# STM32U5Gx register map
File version: 1.0
CPU: CM33 r0p1, little endian, MPU, FPU, 4 interrupt priority bits
Registers are 32-bit, read-write, reset 0x0 unless marked. A register's access mark holds for its fields unless they carry their own. Offsets are from the block's base; [hi:lo] are bit positions; {n}, {i} and the like mark numbered series; 'fields as' and 'values as' point back to an identical list.

## GPDMA1 (part 1 of 2)
Base 0x40020000
Same registers: SEC_GPDMA1 0x50020000
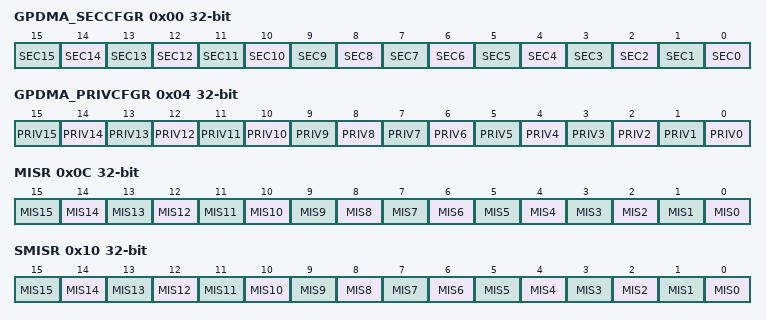
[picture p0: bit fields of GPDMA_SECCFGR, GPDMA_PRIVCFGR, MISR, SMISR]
0x00 GPDMA_SECCFGR — GPDMA secure configuration register
  [n] SEC{n} (n=0..15)
0x04 GPDMA_PRIVCFGR — GPDMA privileged configuration register
  [n] PRIV{n} (n=0..15)
0x0C MISR ro — non-secure masked interrupt status register
  [n] MIS{n} (n=0..15)
0x10 SMISR ro — secure masked interrupt status register
  [n] MIS{n} (n=0..15)
{0x50+0x80*i} GPDMA_C{i}LBAR (i=0..15) — channel x linked-list base address register
  [31:16] LBA — linked-list base address of DMA channel x
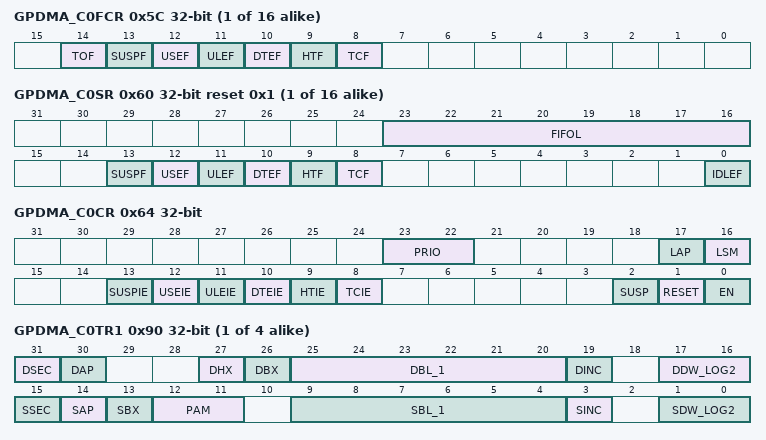
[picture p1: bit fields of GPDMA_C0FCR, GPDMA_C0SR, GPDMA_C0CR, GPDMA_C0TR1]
{0x5C+0x80*i} GPDMA_C{i}FCR wo (i=0..15) — GPDMA channel x flag clear register
  [14] TOF — trigger overrun flag clear
  [13] SUSPF — completed suspension flag clear - 0: no effect - 1: clears the corresponding SUSPF flag
  [12] USEF — user setting error flag clear - 0: no effect - 1: clears the corresponding USEF flag
  [11] ULEF — update link transfer error flag clear - 0: no effect - 1: clears the corresponding ULEF flag
  [10] DTEF — data transfer error flag clear - 0: no effect - 1: clears the corresponding DTEF flag
  [9] HTF — half transfer flag clear - 0: no effect - 1: clears the corresponding HTF flag
  [8] TCF — transfer complete flag clear - 0: no effect - 1: clears the corresponding TCF flag
{0x60+0x80*i} GPDMA_C{i}SR ro reset 0x1 (i=0..15) — channel x status register
  [23:16] FIFOL — monitored FIFO level Number of available write beats in the FIFO, in units of the programmed destination data width (c.f. GPDMA_CxTR1.DDW_LOG2[1:0], i.e. in units of bytes, half-words, or words). Note: After having suspended an active transfer, the user may need to read FIFOL[7:0], additionally to GPDMA_CxBR1.BDNT[15:0] and GPDMA_CxBR1.BRC[10:0] in order to know exactly how many data have been transferred to the destination. Before reading, the user may wait for the transfer to be indeed suspended i.e. GPDMA_CxSR.SUSPF=1.
  [13] SUSPF — completed suspension flag - 0: no completed suspension event - 1: a completed suspension event occurred
  [12] USEF — user setting error flag - 0: no user setting error event - 1: a user setting error event occurred
  [11] ULEF — update link transfer error flag - 0: no update link transfer error event - 1: a master bus error event occurred while updating a linked-list register from memory
  [10] DTEF — data transfer error flag - 0: no data transfer error event - 1: a master bus error event occurred on a data transfer
  [9] HTF — half transfer flag - 0: no half transfer event - 1: an half transfer event occurred An half transfer event is either an half block transfer or an half 2D/repeated block transfer, depending on the transfer complete event mode i.e. GPDMA_CxTR2.TCEM[1:0]. An half block transfer occurs when half of the bytes of the source block size (i.e. rounded up integer of GPDMA_CxBR1.BNDT[15:0]/2) has been transferred to the destination. Half 2D/repeated block transfer occurs when half of the repeated blocks (i.e. rounded up integer of (GPDMA_CxBR1.BRC[10:0]+1)/2) have been transferred to the destination.
  [8] TCF — transfer complete flag - 0: no transfer complete event - 1: a transfer complete event occurred A transfer complete event is either a block transfer complete or a 2D/repeated block transfer complete, or a LLI transfer complete including the upload of the next LLI if any, or the full linked-list completion, depending on the transfer complete event mode i.e. GPDMA_CxTR2.TCEM[1:0].
  [0] IDLEF — idle flag - 0: the channel is not in idle state - 1: the channel is in idle state This idle flag is de-asserted by hardware when the channel is enabled (i.e. is written 1 into GPDMA_CxCR.EN) with a valid channel configuration (i.e. no USEF to be immediately reported). This idle flag is asserted after hard reset or by hardware when the channel is back in idle state (i.e. in suspended or disabled state).
0x64 GPDMA_C0CR — channel x control register
  [23:22] PRIO — priority level of the DMA transfer of the channel x vs others- 00: low priority, low weight- 01: low priority, mid weight- 10: low priority, high weight- 11: high priorityNote: This bit must be written when EN=0. This bit is read-only when EN=1.
  [17] LAP — linked-list allocated portAllocate the master port for the update of the DMA linked-list registers from the memory.- 0: port 0 (AHB) is allocated for the update of the DMA linked-list channel x registers- 1: port 1 (AHB) is allocated for the update of the DMA linked-list channel x registersNote: This bit must be written when EN=0. This bit is read-only when EN=1.
  [16] LSM — Link Step mode:- 0: channel is executed for the full linked-list, and completed at the end (if any) of the last LLI i.e. when GPDMA_CxLLR=0: the 16 low significant bits of the link address are null (LA[15:0]=0) and all the update bits are null i.e. UT1=UB1=UT2=USA=UDA=UB2 =UT3=ULL=0. Then GPDMA_CxBR1.BRC[10:0]=0 and GPDMA_CxBR1.BNDT[15:0]=0.- 1: channel is executed once for the current LLI:* First the (possibly 2D/repeated) block transfer is executed as defined by the current internal register file until that (GPDMA_CxBR1.BRC[10:0]=0 and GPDMA_CxBR1.BNDT[15:0]=0).* Secondly the next linked-list data structure is conditionally uploaded from memory as defined by GPDMA_CxLLR register. Then channel execution is completed.Note: This bit must be written when EN=0. This bit is read-only when EN=1.
  [13] SUSPIE — completed suspension interrupt enable - 0: interrupt disabled - 1: interrupt enabled
  [12] USEIE — user setting error interrupt enable - 0: interrupt disabled - 1: interrupt enabled
  [11] ULEIE — update link transfer error interrupt enable - 0: interrupt disabled - 1: interrupt enabled
  [10] DTEIE — data transfer error interrupt enable - 0: interrupt disabled - 1: interrupt enabled
  [9] HTIE — half transfer complete interrupt enable - 0: interrupt disabled - 1: interrupt enabled
  [8] TCIE — transfer complete interrupt enable - 0: interrupt disabled - 1: interrupt enabled
  [2] SUSP — suspend - 0: write: resume channel, read: channel not suspended - 1: write: suspend channel, read: channel suspended Writing 1 into the field RESET (bit 1) causes the hardware to de-assert this bit, whatever is written into this bit 2. Else: Software must write 1 in order to suspend an active channel i.e. a channel with an on-going DMA transfer over its master ports. Software must write 0 in order to resume a suspended channel, following the programming sequence in Figure 3: DMA channel suspend and resume sequence.
  [1] RESET — reset - 0: no channel reset - 1: channel reset This bit is write only. Writing 0 has no impact. Writing 1 implies/will imply the reset of the FIFO, the reset of the channel internal state, and the reset of the SUSP and EN bits, whatever is written in respectively bit 2 and bit 0.
  [0] EN — enable - 0: write: ignored, read: channel disabled - 1: write: enable channel, read: channel enabled Writing 1 into the field RESET (bit 1) causes the hardware to de-assert this bit, whatever is written into this bit 0. Else: * this bit is de-asserted by hardware when there is a transfer error (master bus error or user setting error) or when there is a channel transfer complete (channel ready to be configured, e.g. if LSM=1 at the end of a single execution of the LLI). * Else, this bit can be asserted by software. Writing 0 into this EN bit is ignored.
{0x90+0x80*i} GPDMA_C{i}TR1 (i=0..3) — GPDMA channel x transfer register 1
  [31] DSEC — security attribute of the DMA transfer to the destinationThis is a secure register bit.This bit can only be read by a secure software. This bit must be written by a secure software when GPDMA_SECCFGR.SECx=1. A secure write is ignored when GPDMA_SECCFGR.SECx=0.When is de-asserted GPDMA_SECCFGR.SECx, this bit is also de-asserted by hardware (on a secure reconfiguration of the channel as non-secure), and the DMA transfer to the destination is non-secure.If GPDMA_SECCFGR.SECx=1 (and a secure access):- 0: non-secure- 1: secure
  [30] DAP — destination allocated portAllocate the master port to the destination transfer.- 0: port 0 (AHB) is allocated to the destination transfer- 1: port 1 (AHB) is allocated to the destination transferNote: This bit must be written when EN=0. This bit is read-only when EN=1.
  [27] DHX — destination half-word exchangeIf destination data size is shorter than a word, this bit is ignored.If destination data size is a word:- 0: no halfword-based exchange within word- 1: the two consecutive (post PAM) half-words are exchanged in each destination word
  [26] DBX — destination byte exchangeIf destination data size is a byte, this bit is ignored.If destination data size is not a byte:- 0: no byte-based exchange within half-word- 1: the two consecutive (post PAM) bytes are exchanged in each destination half-word
  [25:20] DBL_1 — destination burst length minus 1 , between 0 and 63.Burst length unit is one data a.k.a. beat within a burst.If DBL_1[5:0]=0, then burst can be named as single.Each data/beat has a width defined by the destination data width i.e. DDW_LOG2[1:0].Note: A burst transfer must have an aligned address with its data width (c.f. start address GPDMA_CxDAR[2:0] and address offset GPDMA_CxTR3.DAO[2:0] vs DDW_LOG2[1:0]). Else a user setting error is reported and none transfer is issued.Note: If a burst transfer would have crossed a 1kB address boundary on a AHB transfer, internally DMA modifies and shortens the programmed burst into single(s) or burst(s) of lower length, to be compliant with the AHB protocol.Note: If a burst transfer is of length greater than the FIFO size of the channel x, internally DMA modifies and shortens the programmed burst into single(s) or burst(s) of lower length, to be compliant with the FIFO size. Transfer performance is lower, with DMA re-arbitration between effective and lower burst(s)/singles, but data integrity is guaranteed.
  [19] DINC — destination incrementing burst- 0: fixed burst- 1: contiguously incremented burstThe destination address, pointed by DMA_CxDAR, is either kept constant after a burst beat/single transfer, or is incremented by the offset value corresponding to a contiguous data after a burst beat/single transfer.
  [17:16] DDW_LOG2 — binary logarithm of the destination data width of a burst, in bytes- 00: byte- 01: half-word (2 bytes)- 10: word (4 bytes)- 11: a user setting error is reported and no transfer is issued.Note: Setting a 8-byte data width is causing a user setting error to be reported and none transfer is issued.Note: A destination burst transfer must have an aligned address with its data width (c.f. start address GPDMA_CxDAR[2:0] and address offset GPDMA_CxTR3.DAO[2:0] vs DDW_LOG2[1:0]). Else a user setting error is reported and none transfer is issued.Note: When configured in packing mode (i.e. if PAM[1]=1 and destination data width different from source data width), a source block size must be a multiple of the destination data width (c.f. GPDMA_CxBR1.BNDT[2:0] vs DDW_LOG2[1:0]). Else a user setting error is reported and none transfer is issued.
  [15] SSEC — security attribute of the DMA transfer from the sourceThis is a secure register bit.This bit can only be read by a secure software. This bit must be written by a secure software when GPDMA_SECCFGR.SECx=1. A secure write is ignored when GPDMA_SECCFGR.SECx=0.When is de-asserted GPDMA_SECCFGR.SECx, this bit is also de-asserted by hardware (on a secure reconfiguration of the channel as non-secure), and the DMA transfer from the source is non-secure.If GPDMA_SECCFGR.SECx=1 (and a secure access):- 0: non-secure- 1: secure
  [14] SAP — source allocated portAllocate the master port to the source transfer.- 0: port 0 (AHB) is allocated to the source transfer- 1: port 1 (AHB) is allocated to the source transferNote: This bit must be written when EN=0. This bit is read-only when EN=1.
  [13] SBX — source byte exchange within the unaligned half-word of each source wordIf source data width is shorter than a word, this bit is ignored.If source data width is a word:- 0: no byte-based exchange within the unaligned half-word of each source word- 1: the two consecutive bytes within the unaligned half-word of each source word are exchanged
  [12:11] PAM
  [9:4] SBL_1 — source burst length minus 1 , between 0 and 63.Burst length unit is one data a.k.a. beat within a burst.If SBL_1[5:0]=0, then burst can be named as single.Each data/beat has a width defined by the source data width i.e. SDW_LOG2[1:0].Note: A burst transfer must have an aligned address (c.f. start address GPDMA_CxSAR and address offset GPDMA_CxTR3.SAO) with its data width (byte, half-word or word). Else a user setting error is reported and none transfer is issued.Note: If a burst transfer would have crossed a 1kB address boundary on a AHB transfer, internally DMA modifies and shortens the programmed burst into single(s) or burst(s) of lower length, to be compliant with the AHB protocol.Note: If a burst transfer is of length greater than the FIFO size of the channel x, internally DMA modifies and shortens the programmed burst into single(s) or burst(s) of lower length, to be compliant with the FIFO size. Transfer performance is lower, with DMA re-arbitration between effective and lower burst(s)/singles, but data integrity is guaranteed.
  [3] SINC — source incrementing burst- 0: fixed burst- 1: contiguously incremented burstThe source address, pointed by DMA_CxSAR, is either kept constant after a burst beat/single transfer, or is incremented by the offset value corresponding to a contiguous data after a burst beat/single transfer.
  [1:0] SDW_LOG2 — binary logarithm of the source data width of a burst, in bytes- 00: byte- 01: half-word (2 bytes)- 10: word (4 bytes)- 11: a user setting error is reported and no transfer is issued.Note: Setting a 8-byte data width is causing a user setting error to be reported and none transfer is issued.Note: a source block size must be a multiple of the source data width (c.f. GPDMA_CxBR1.BNDT[2:0] vs SDW_LOG2[1:0]). Else a user setting error is reported and none transfer is issued.Note: A source burst transfer must have an aligned address with its data width (c.f. start address GPDMA_CxSAR[2:0] and address offset GPDMA_CxTR3.SAO[2:0] vs SDW_LOG2[1:0]). Else a user setting error is reported and none transfer is issued.
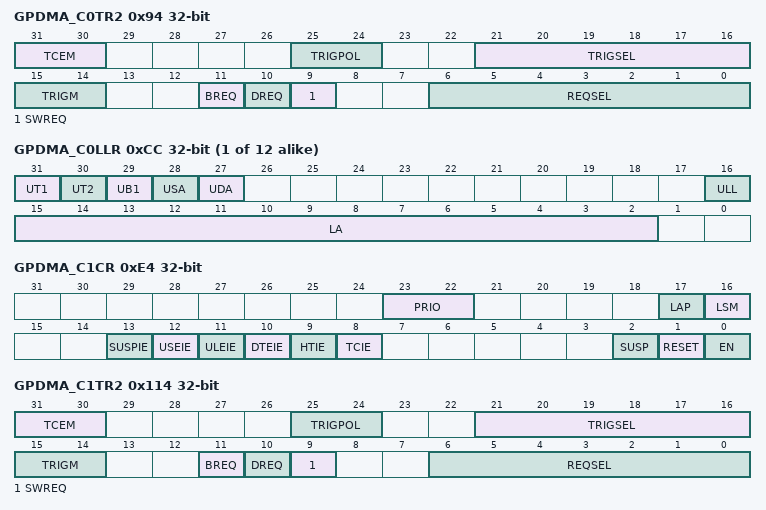
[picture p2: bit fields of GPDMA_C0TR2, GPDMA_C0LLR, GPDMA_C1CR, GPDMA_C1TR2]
0x94 GPDMA_C0TR2 — GPDMA channel x transfer register 2
  [31:30] TCEM — Transfer complete event mode Defines the transfer granularity for the transfer complete (and half transfer complete) event generation. - 00: at block level (i.e. when GPDMA_CxBR1.BNDT[15:0]= 0): the complete (and the half) transfer event is generated at the (respectively half of the) end of a block. Note: If the initial LLI0 data transfer is null/void (i.e. directly programmed by the internal register file with GPDMA_CxBR1.BNDT[15:0]=0), then neither the complete transfer event nor the half transfer event is generated. - 01: channel x=0 to 11: same as 00 ;channel x=12 to 15: at 2D/repeated block level (i.e. when GPDMA_CxBR1.BRC[10:0]= 0 and GPDMA_CxBR1.BNDT[15:0]= 0): the complete (and the half) transfer event is generated at the end (respectively half of the end) of the 2D/repeated block Note: If the initial LLI0 data transfer is null/void (i.e. directly programmed by the internal register file with GPDMA_CxBR1.BNDT[15:0]=0), then neither the complete transfer event nor the half transfer event is generated. - 10: at LLI level: the complete transfer event is generated at the end of the LLI transfer, including the update of the LLI if any. The half transfer event is generated at the half of the LLI data transfer (the LLI data transfer being a block or a 2D/repeated block transfer), if any data transfer. Note: If the initial LLI0 data transfer is null/void (i.e. directly programmed by the internal register file with GPDMA_CxBR1.BNDT[15:0]=0), then the half transfer event is not generated, and the transfer complete event is generated when is completed the loading of the LLI1. - 11: at channel level: the complete transfer event is generated at the end of the last LLI transfer. The half transfer event is generated at the half of the data transfer of the last LLI. The last LLI is the one that updates the link address GPDMA_CxLLR.LA[15:2] to zero and that clears all the update bits - UT1, UT2, UB1, USA, UDA, if present UT3, UB2 and ULL - of the GPDMA_CxLLR register. If the channel transfer is continuous/infinite, no event is generated.
  [25:24] TRIGPOL — Trigger event polarity Defines the polarity of the selected trigger event input defined by TRIGSEL[5:0]. - 00: no trigger. Masked trigger event. - 01: trigger on the rising edge - 10: trigger on the falling edge - 11: same as 00
  [21:16] TRIGSEL — Trigger event input selection Note: Selects the trigger event input as per Table 13 of the DMA transfer, with an active trigger event if TRIGPOL[1:0] !=00.
  [15:14] TRIGM — Trigger mode
  [11] BREQ
  [10] DREQ — Destination hardware request If the channel x is activated (i.e. GPDMA_CxCR.EN is asserted) with SWREQ=1 (i.e. software request for a memory-to-memory transfer), this bit is ignored. Else: - 0: the selected hardware request is driven by a source peripheral (i.e. this request signal is taken into account by the DMA transfer scheduler over the source/read port) - 1: the selected hardware request is driven by a destination peripheral (.e. this request signal is taken into account by the DMA transfer scheduler over the destination/write port)
  [9] SWREQ — Software request When GPDMA_CxCR.EN is asserted, this field is internally taken into account: - 0: no software request. The selected hardware request REQSEL[6:0] is taken into account. - 1: software request (for a memory-to-memory transfer). And the default selected hardware request as per REQSEL[6:0] is ignored.
  [6:0] REQSEL — DMA hardware request selection If the channel x is activated (i.e. GPDMA_CxCR.EN is asserted) with SWREQ=1 (i.e. software request for a memory-to-memory transfer), this bit is ignored. Else, the selected hardware request as per Table 12 is internally taken into account. Note: The user must not assign a same input hardware request (i.e. a same REQSEL[6:0] value) to different active DMA channels (i.e. if GPDMA_CxCR.EN=1 and GPDMA_CxTR2.SWREQ=0 for the related x channels). In other words, DMA is not intended to hardware support the case of simultaneous enabled channels having been -incorrectly- configured with a same hardware peripheral request signal, and there is no user setting error reporting.
{0x98+0x80*i} GPDMA_C{i}BR1 (i=0..11) — GPDMA channel x block register 1
  [15:0] BNDT — block number of data bytes to transfer from the source
{0x9C+0x80*i} GPDMA_C{i}SAR (i=0..15) — GPDMA channel x source address register
  [31:0] SA — source address
{0xA0+0x80*i} GPDMA_C{i}DAR (i=0..15) — GPDMA channel x destination address register
  [31:0] DA — destination address
{0xCC+0x80*i} GPDMA_C{i}LLR (i=0..11) — GPDMA channel x linked-list address register
  [31] UT1 — Update GPDMA_CxTR1 from memory This bit controls the update of the GPDMA_CxTR1 register from the memory during the link transfer. - 0: no GPDMA_CxTR1 update - 1: GPDMA_CxTR1 update
  [30] UT2 — Update GPDMA_CxTR2 from memory This bit controls the update of the GPDMA_CxTR2 register from the memory during the link transfer. - 0: no GPDMA_CxTR2 update - 1: GPDMA_CxTR2 update
  [29] UB1 — Update GPDMA_CxBR1 from memory This bit controls the update of the GPDMA_CxBR1 register from the memory during the link transfer. If UB1=0 and if GPDMA_CxLLR != 0, the linked-list is not completed. Then GPDMA_CxBR1.BNDT[15:0] is restored to the programmed value after data transfer is completed and before the link transfer. - 0: no GPDMA_CxBR1 update (GPDMA_CxBR1.BNDT[15:0] is restored, if any link transfer) - 1: GPDMA_CxBR1 update
  [28] USA — Update GPDMA_CxSAR from memory This bit controls the update of the GPDMA_CxSAR register from the memory during the link transfer. - 0: no GPDMA_CxSAR update - 1: GPDMA_CxSAR update
  [27] UDA — Update GPDMA_CxDAR from memory This bit controls the update of the GPDMA_CxDAR register from the memory during the link transfer. - 0: no GPDMA_CxDAR update - 1: GPDMA_CxDAR update
  [16] ULL — Update GPDMA_CxLLR from memory This bit controls the update of the GPDMA_CxLLR register from the memory during the link transfer. - 0: no GPDMA_CxLLR update - 1: GPDMA_CxLLR update
  [15:2] LA — pointer (16-bit low significant address) to the next linked-list data structure If UT1=UT2=UB1=USA=UDA=ULL=0 and if LA[15:2]=0: the current LLI is the last one. The channel transfer is completed without any update of the linked-list DMA register file. Else, this field is the pointer to the memory address offset from which the next linked-list data structure will be automatically fetched from, once the data transfer is completed, in order to conditionally update the linked-list DMA internal register file i.e. possibly GPDMA_CxCTR1, GPDMA_CxTR2, GPDMA_CxBR1, GPDMA_CxSAR, GPDMA_CxDAR and GPDMA_CxLLR. Note: The user should program the pointer to be 32-bit aligned. The two low significant bits are write ignored.
0xE4 GPDMA_C1CR — channel x control register
  [23:22] PRIO — priority level of the DMA transfer of the channel x vs others- 00: low priority, low weight- 01: low priority, mid weight- 10: low priority, high weight- 11: high priorityNote: This bit must be written when EN=0. This bit is read-only when EN=1.
  [17] LAP — linked-list allocated portAllocate the master port for the update of the DMA linked-list registers from the memory.- 0: port 0 (AHB) is allocated for the update of the DMA linked-list channel x registers- 1: port 1 (AHB) is allocated for the update of the DMA linked-list channel x registersNote: This bit must be written when EN=0. This bit is read-only when EN=1.
  [16] LSM — Link Step mode:- 0: channel is executed for the full linked-list, and completed at the end (if any) of the last LLI i.e. when GPDMA_CxLLR=0: the 16 low significant bits of the link address are null (LA[15:0]=0) and all the update bits are null i.e. UT1=UB1=UT2=USA=UDA=UB2 =UT3=ULL=0. Then GPDMA_CxBR1.BRC[10:0]=0 and GPDMA_CxBR1.BNDT[15:0]=0.- 1: channel is executed once for the current LLI:* First the (possibly 2D/repeated) block transfer is executed as defined by the current internal register file until that (GPDMA_CxBR1.BRC[10:0]=0 and GPDMA_CxBR1.BNDT[15:0]=0).* Secondly the next linked-list data structure is conditionally uploaded from memory as defined by GPDMA_CxLLR register. Then channel execution is completed.Note: This bit must be written when EN=0. This bit is read-only when EN=1.
  [13] SUSPIE — completed suspension interrupt enable - 0: interrupt disabled - 1: interrupt enabled
  [12] USEIE — user setting error interrupt enable - 0: interrupt disabled - 1: interrupt enabled
  [11] ULEIE — update link transfer error interrupt enable - 0: interrupt disabled - 1: interrupt enabled
  [10] DTEIE — data transfer error interrupt enable - 0: interrupt disabled - 1: interrupt enabled
  [9] HTIE — half transfer complete interrupt enable - 0: interrupt disabled - 1: interrupt enabled
  [8] TCIE — transfer complete interrupt enable - 0: interrupt disabled - 1: interrupt enabled
  [2] SUSP — suspend - 0: write: resume channel, read: channel not suspended - 1: write: suspend channel, read: channel suspended Writing 1 into the field RESET (bit 1) causes the hardware to de-assert this bit, whatever is written into this bit 2. Else: Software must write 1 in order to suspend an active channel i.e. a channel with an on-going DMA transfer over its master ports. Software must write 0 in order to resume a suspended channel, following the programming sequence in Figure 3: DMA channel suspend and resume sequence.
  [1] RESET
  [0] EN — enable - 0: write: ignored, read: channel disabled - 1: write: enable channel, read: channel enabled Writing 1 into the field RESET (bit 1) causes the hardware to de-assert this bit, whatever is written into this bit 0. Else: * this bit is de-asserted by hardware when there is a transfer error (master bus error or user setting error) or when there is a channel transfer complete (channel ready to be configured, e.g. if LSM=1 at the end of a single execution of the LLI). * Else, this bit can be asserted by software. Writing 0 into this EN bit is ignored.
0x114 GPDMA_C1TR2 — GPDMA channel x transfer register 2
  [31:30] TCEM — Transfer complete event mode Defines the transfer granularity for the transfer complete (and half transfer complete) event generation. - 00: at block level (i.e. when GPDMA_CxBR1.BNDT[15:0]= 0): the complete (and the half) transfer event is generated at the (respectively half of the) end of a block. Note: If the initial LLI0 data transfer is null/void (i.e. directly programmed by the internal register file with GPDMA_CxBR1.BNDT[15:0]=0), then neither the complete transfer event nor the half transfer event is generated. - 01: channel x=0 to 11: same as 00 ;channel x=12 to 15: at 2D/repeated block level (i.e. when GPDMA_CxBR1.BRC[10:0]= 0 and GPDMA_CxBR1.BNDT[15:0]= 0): the complete (and the half) transfer event is generated at the end (respectively half of the end) of the 2D/repeated block Note: If the initial LLI0 data transfer is null/void (i.e. directly programmed by the internal register file with GPDMA_CxBR1.BNDT[15:0]=0), then neither the complete transfer event nor the half transfer event is generated. - 10: at LLI level: the complete transfer event is generated at the end of the LLI transfer, including the update of the LLI if any. The half transfer event is generated at the half of the LLI data transfer (the LLI data transfer being a block or a 2D/repeated block transfer), if any data transfer. Note: If the initial LLI0 data transfer is null/void (i.e. directly programmed by the internal register file with GPDMA_CxBR1.BNDT[15:0]=0), then the half transfer event is not generated, and the transfer complete event is generated when is completed the loading of the LLI1. - 11: at channel level: the complete transfer event is generated at the end of the last LLI transfer. The half transfer event is generated at the half of the data transfer of the last LLI. The last LLI is the one that updates the link address GPDMA_CxLLR.LA[15:2] to zero and that clears all the update bits - UT1, UT2, UB1, USA, UDA, if present UT3, UB2 and ULL - of the GPDMA_CxLLR register. If the channel transfer is continuous/infinite, no event is generated.
  [25:24] TRIGPOL — Trigger event polarity Defines the polarity of the selected trigger event input defined by TRIGSEL[5:0]. - 00: no trigger. Masked trigger event. - 01: trigger on the rising edge - 10: trigger on the falling edge - 11: same as 00
  [21:16] TRIGSEL — Trigger event input selection Note: Selects the trigger event input as per Table 13 of the DMA transfer, with an active trigger event if TRIGPOL[1:0] !=00.
  [15:14] TRIGM — TRIGM mode
  [11] BREQ
  [10] DREQ — Destination hardware request If the channel x is activated (i.e. GPDMA_CxCR.EN is asserted) with SWREQ=1 (i.e. software request for a memory-to-memory transfer), this bit is ignored. Else: - 0: the selected hardware request is driven by a source peripheral (i.e. this request signal is taken into account by the DMA transfer scheduler over the source/read port) - 1: the selected hardware request is driven by a destination peripheral (.e. this request signal is taken into account by the DMA transfer scheduler over the destination/write port)
  [9] SWREQ — Software request When GPDMA_CxCR.EN is asserted, this field is internally taken into account: - 0: no software request. The selected hardware request REQSEL[6:0] is taken into account. - 1: software request (for a memory-to-memory transfer). And the default selected hardware request as per REQSEL[6:0] is ignored.
  [6:0] REQSEL — DMA hardware request selection If the channel x is activated (i.e. GPDMA_CxCR.EN is asserted) with SWREQ=1 (i.e. software request for a memory-to-memory transfer), this bit is ignored. Else, the selected hardware request as per Table 12 is internally taken into account. Note: The user must not assign a same input hardware request (i.e. a same REQSEL[6:0] value) to different active DMA channels (i.e. if GPDMA_CxCR.EN=1 and GPDMA_CxTR2.SWREQ=0 for the related x channels). In other words, DMA is not intended to hardware support the case of simultaneous enabled channels having been -incorrectly- configured with a same hardware peripheral request signal, and there is no user setting error reporting.
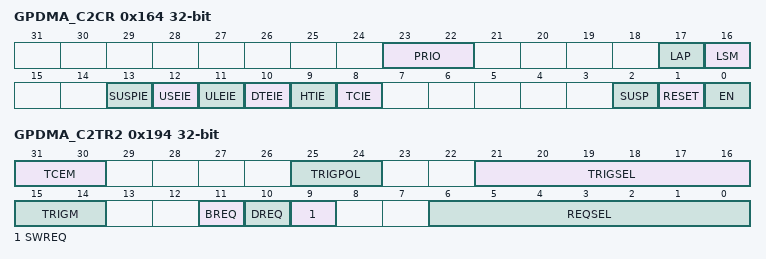
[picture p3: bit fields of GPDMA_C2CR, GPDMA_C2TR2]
0x164 GPDMA_C2CR — channel x control register
  fields as GPDMA_C1CR
0x194 GPDMA_C2TR2 — GPDMA channel x transfer register 2
  fields as GPDMA_C0TR2
